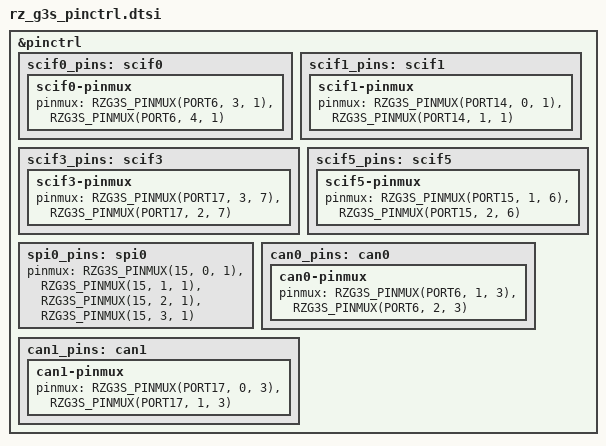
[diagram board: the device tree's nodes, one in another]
/*
 * Copyright (c) 2024 EPAM Systems
 *
 * SPDX-License-Identifier: Apache-2.0
 */

#include <zephyr/dt-bindings/gpio/gpio.h>
#include <zephyr/dt-bindings/pinctrl/renesas/pinctrl-r9a08g045.h>

&pinctrl {
	/omit-if-no-ref/ scif0_pins: scif0 {
		scif0-pinmux {
			pinmux = <RZG3S_PINMUX(PORT6, 3, 1)>, /* TXD */
				 <RZG3S_PINMUX(PORT6, 4, 1)>; /* RXD */
		};
	};

	/omit-if-no-ref/ scif1_pins: scif1 {
		scif1-pinmux {
			pinmux = <RZG3S_PINMUX(PORT14, 0, 1)>, /* TXD */
				 <RZG3S_PINMUX(PORT14, 1, 1)>; /* RXD */
		};
	};

	/omit-if-no-ref/ scif3_pins: scif3 {
		scif3-pinmux {
			pinmux = <RZG3S_PINMUX(PORT17, 3, 7)>, /* TXD */
				 <RZG3S_PINMUX(PORT17, 2, 7)>; /* RXD */
		};
	};

	/omit-if-no-ref/ scif5_pins: scif5 {
		scif5-pinmux {
			pinmux = <RZG3S_PINMUX(PORT15, 1, 6)>, /* RXD */
				 <RZG3S_PINMUX(PORT15, 2, 6)>; /* TXD */
		};
	};

	/omit-if-no-ref/ spi0_pins: spi0 {
		pinmux = <RZG3S_PINMUX(15, 0, 1)>, /* CK */
			 <RZG3S_PINMUX(15, 1, 1)>, /* MOSI */
			 <RZG3S_PINMUX(15, 2, 1)>, /* MISO */
			 <RZG3S_PINMUX(15, 3, 1)>; /* SSL */
	};

	/omit-if-no-ref/ can0_pins: can0 {
		can0-pinmux {
			pinmux = <RZG3S_PINMUX(PORT6, 1, 3)>, /* TX */
				 <RZG3S_PINMUX(PORT6, 2, 3)>; /* RX */
		};
	};

	/omit-if-no-ref/ can1_pins: can1 {
		can1-pinmux {
			pinmux = <RZG3S_PINMUX(PORT17, 0, 3)>, /* TX */
				 <RZG3S_PINMUX(PORT17, 1, 3)>; /* RX */
		};
	};
};
